# SF32LB58x register map
File version: 1.0
CPU: CM33 r0p1, little endian, MPU, FPU, 3 interrupt priority bits
Registers are 32-bit, read-write, reset 0x0 unless marked. A register's access mark holds for its fields unless they carry their own. Offsets are from the block's base; [hi:lo] are bit positions; {n}, {i} and the like mark numbered series.

## HPSYS_RCC
Base 0x40000000
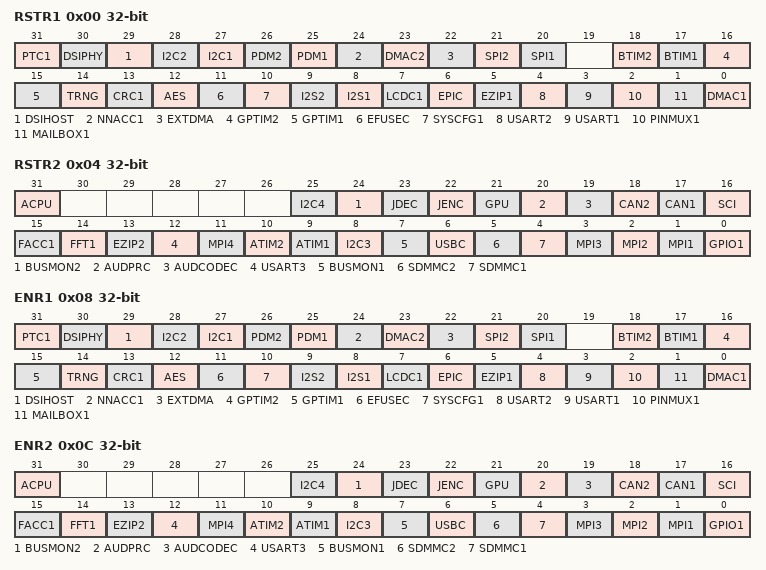
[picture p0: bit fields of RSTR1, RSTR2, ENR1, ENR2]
0x00 RSTR1 — Reset Register 1
  [31] PTC1 — 0 - no reset; 1 - reset
  [30] DSIPHY — 0 - no reset; 1 - reset
  [29] DSIHOST — 0 - no reset; 1 - reset
  [28] I2C2 — 0 - no reset; 1 - reset
  [27] I2C1 — 0 - no reset; 1 - reset
  [26] PDM2 — 0 - no reset; 1 - reset
  [25] PDM1 — 0 - no reset; 1 - reset
  [24] NNACC1 — 0 - no reset; 1 - reset
  [23] DMAC2 — 0 - no reset; 1 - reset
  [22] EXTDMA — 0 - no reset; 1 - reset
  [21] SPI2 — 0 - no reset; 1 - reset
  [20] SPI1 — 0 - no reset; 1 - reset
  [18] BTIM2 — 0 - no reset; 1 - reset
  [17] BTIM1 — 0 - no reset; 1 - reset
  [16] GPTIM2 — 0 - no reset; 1 - reset
  [15] GPTIM1 — 0 - no reset; 1 - reset
  [14] TRNG — 0 - no reset; 1 - reset
  [13] CRC1 — 0 - no reset; 1 - reset
  [12] AES — 0 - no reset; 1 - reset
  [11] EFUSEC — 0 - no reset; 1 - reset
  [10] SYSCFG1 — 0 - no reset; 1 - reset
  [9] I2S2 — 0 - no reset; 1 - reset
  [8] I2S1 — 0 - no reset; 1 - reset
  [7] LCDC1 — 0 - no reset; 1 - reset
  [6] EPIC — 0 - no reset; 1 - reset
  [5] EZIP1 — 0 - no reset; 1 - reset
  [4] USART2 — 0 - no reset; 1 - reset
  [3] USART1 — 0 - no reset; 1 - reset
  [2] PINMUX1 — 0 - no reset; 1 - reset
  [1] MAILBOX1 — 0 - no reset; 1 - reset
  [0] DMAC1 — 0 - no reset; 1 - reset
0x04 RSTR2 — Reset Register 2
  [31] ACPU — 0 - no reset; 1 - reset
  [25] I2C4 — 0 - no reset; 1 - reset
  [24] BUSMON2 — 0 - no reset; 1 - reset
  [23] JDEC — 0 - no reset; 1 - reset
  [22] JENC — 0 - no reset; 1 - reset
  [21] GPU — 0 - no reset; 1 - reset
  [20] AUDPRC — 0 - no reset; 1 - reset
  [19] AUDCODEC — 0 - no reset; 1 - reset
  [18] CAN2 — 0 - no reset; 1 - reset
  [17] CAN1 — 0 - no reset; 1 - reset
  [16] SCI — 0 - no reset; 1 - reset
  [15] FACC1 — 0 - no reset; 1 - reset
  [14] FFT1 — 0 - no reset; 1 - reset
  [13] EZIP2 — 0 - no reset; 1 - reset
  [12] USART3 — 0 - no reset; 1 - reset
  [11] MPI4 — 0 - no reset; 1 - reset
  [10] ATIM2 — 0 - no reset; 1 - reset
  [9] ATIM1 — 0 - no reset; 1 - reset
  [8] I2C3 — 0 - no reset; 1 - reset
  [7] BUSMON1 — 0 - no reset; 1 - reset
  [6] USBC — 0 - no reset; 1 - reset
  [5] SDMMC2 — 0 - no reset; 1 - reset
  [4] SDMMC1 — 0 - no reset; 1 - reset
  [3] MPI3 — 0 - no reset; 1 - reset
  [2] MPI2 — 0 - no reset; 1 - reset
  [1] MPI1 — 0 - no reset; 1 - reset
  [0] GPIO1 — 0 - no reset; 1 - reset
0x08 ENR1 — Enable Register 1
  [31] PTC1 — 0 - disabled; 1 - enabled
  [30] DSIPHY — 0 - disabled; 1 - enabled
  [29] DSIHOST — 0 - disabled; 1 - enabled
  [28] I2C2 — 0 - disabled; 1 - enabled
  [27] I2C1 — 0 - disabled; 1 - enabled
  [26] PDM2 — 0 - disabled; 1 - enabled
  [25] PDM1 — 0 - disabled; 1 - enabled
  [24] NNACC1 — 0 - disabled; 1 - enabled
  [23] DMAC2 — 0 - disabled; 1 - enabled
  [22] EXTDMA — 0 - disabled; 1 - enabled
  [21] SPI2 — 0 - disabled; 1 - enabled
  [20] SPI1 — 0 - disabled; 1 - enabled
  [18] BTIM2 — 0 - disabled; 1 - enabled
  [17] BTIM1 — 0 - disabled; 1 - enabled
  [16] GPTIM2 — 0 - disabled; 1 - enabled
  [15] GPTIM1 — 0 - disabled; 1 - enabled
  [14] TRNG — 0 - disabled; 1 - enabled
  [13] CRC1 — 0 - disabled; 1 - enabled
  [12] AES — 0 - disabled; 1 - enabled
  [11] EFUSEC — 0 - disabled; 1 - enabled
  [10] SYSCFG1 — 0 - disabled; 1 - enabled
  [9] I2S2 — 0 - disabled; 1 - enabled
  [8] I2S1 — 0 - disabled; 1 - enabled
  [7] LCDC1 — 0 - disabled; 1 - enabled
  [6] EPIC — 0 - disabled; 1 - enabled
  [5] EZIP1 — 0 - disabled; 1 - enabled
  [4] USART2 — 0 - disabled; 1 - enabled
  [3] USART1 — 0 - disabled; 1 - enabled
  [2] PINMUX1 — 0 - disabled; 1 - enabled
  [1] MAILBOX1 — 0 - disabled; 1 - enabled
  [0] DMAC1 — 0 - disabled; 1 - enabled
0x0C ENR2 — Enable Register 2
  [31] ACPU — 0 - disabled; 1 - enabled
  [25] I2C4 — 0 - disabled; 1 - enabled
  [24] BUSMON2 — 0 - disabled; 1 - enabled
  [23] JDEC — 0 - disabled; 1 - enabled
  [22] JENC — 0 - disabled; 1 - enabled
  [21] GPU — 0 - disabled; 1 - enabled
  [20] AUDPRC — 0 - disabled; 1 - enabled
  [19] AUDCODEC — 0 - disabled; 1 - enabled
  [18] CAN2 — 0 - disabled; 1 - enabled
  [17] CAN1 — 0 - disabled; 1 - enabled
  [16] SCI — 0 - disabled; 1 - enabled
  [15] FACC1 — 0 - disabled; 1 - enabled
  [14] FFT1 — 0 - disabled; 1 - enabled
  [13] EZIP2 — 0 - disabled; 1 - enabled
  [12] USART3 — 0 - disabled; 1 - enabled
  [11] MPI4 — 0 - disabled; 1 - enabled
  [10] ATIM2 — 0 - disabled; 1 - enabled
  [9] ATIM1 — 0 - disabled; 1 - enabled
  [8] I2C3 — 0 - disabled; 1 - enabled
  [7] BUSMON1 — 0 - disabled; 1 - enabled
  [6] USBC — 0 - disabled; 1 - enabled
  [5] SDMMC2 — 0 - disabled; 1 - enabled
  [4] SDMMC1 — 0 - disabled; 1 - enabled
  [3] MPI3 — 0 - disabled; 1 - enabled
  [2] MPI2 — 0 - disabled; 1 - enabled
  [1] MPI1 — 0 - disabled; 1 - enabled
  [0] GPIO1 — 0 - disabled; 1 - enabled
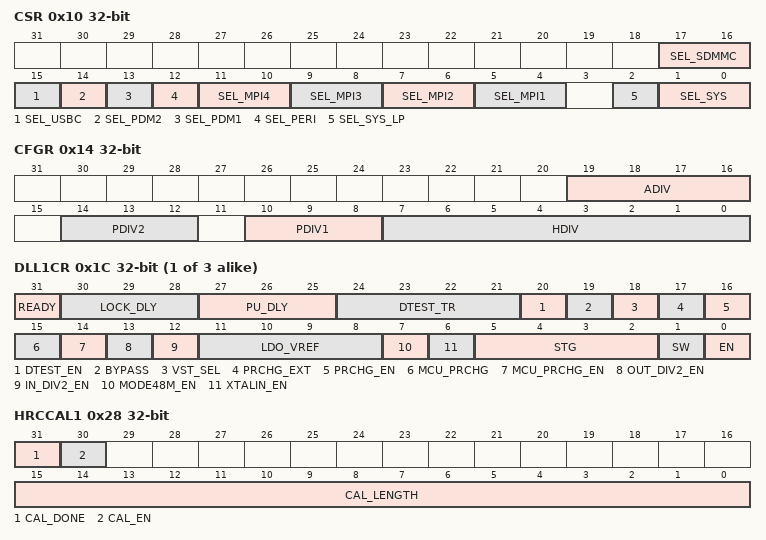
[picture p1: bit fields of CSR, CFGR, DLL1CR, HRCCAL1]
0x10 CSR — Clock Select Register
  [17:16] SEL_SDMMC — select SDMMC function clock 0 - clk_sys; 1 - reserved; 2 - dll2; 3 - dll3
  [15] SEL_USBC — select USB source clock 0 - clk_sys; 1 - dll3
  [14] SEL_PDM2 — 0 - clk_sys; 1 - dll2
  [13] SEL_PDM1 — 0 - clk_sys; 1 - dll2
  [12] SEL_PERI — select clk_peri source used by USART/SPI/CAN/I2C 0 - hrc48; 1 - hxt48
  [2n+3:2n+2] SEL_MPI{n} (n=1..4) — selet MPI{n} function clock 0 - clk_sys; 1 - reserved; 2 - dll2; 3 - dll3
  [2] SEL_SYS_LP — select clk_sys source 0 - selected by SEL_SYS; 1 - clk_lp
  [1:0] SEL_SYS — select clk_sys source 0 - hrc48; 1 - hxt48; 2 - reserved; 3 - dll1
0x14 CFGR — Clock Configuration Register
  [19:16] ADIV — hclk_auxsys = clk_sys / ADIV if ADIV=0, hclk_auxsys = clk_sys
  [14:12] PDIV2 — pclk2 = hclk / (2^PDIV2), by default divided by 128
  [10:8] PDIV1 — pclk1 = hclk / (2^PDIV1), by default divided by 2
  [7:0] HDIV — hclk = hclk_auxsys / HDIV = clk_sys / (ADIV*HDIV) if HDIV=0, hclk = hclk_auxsys
0x18 USBCR — USBC Register
  [2:0] DIV — USB function clock is USB source clock divided by DIV. After divider, USB function clock must be 60MHz.
{0x18+4i} DLL{i}CR (i=1..3) — DLL{i} Control Register
  [31] READY — 0: dll not ready 1: dll ready
  [30:28] LOCK_DLY
  [27:25] PU_DLY
  [24:21] DTEST_TR
  [20] DTEST_EN
  [19] BYPASS
  [18] VST_SEL
  [17] PRCHG_EXT
  [16] PRCHG_EN
  [15] MCU_PRCHG
  [14] MCU_PRCHG_EN
  [13] OUT_DIV2_EN — 0: dll output not divided 1: dll output divided by 2
  [12] IN_DIV2_EN
  [11:8] LDO_VREF
  [7] MODE48M_EN
  [6] XTALIN_EN
  [5:2] STG — DLL lock freqency is decided by STG. DLL output frequency is: 0: 192MHz(if OUT_DIV2_EN=1) or 384MHz(if OUT_DIV2_EN=0) 1: 168MHz(if OUT_DIV2_EN=1) or 336MHz(if OUT_DIV2_EN=0) 2: 144MHz(if OUT_DIV2_EN=1) or 288MHz(if OUT_DIV2_EN=0) 3: 120MHz(if OUT_DIV2_EN=1) or 240MHz(if OUT_DIV2_EN=0) 4: 96MHz(if OUT_DIV2_EN=1) or 192MHz(if OUT_DIV2_EN=0)
  [1] SW
  [0] EN — 0: dll disabled 1: dll enabled
0x28 HRCCAL1 — HRC Calibration Register 1
  [31] CAL_DONE — Calibration done. After a new calibration started, results should be processed only when cal_done asserted.
  [30] CAL_EN — Calibration enble. Set to 0 to clear result, then set to 1 to start a new calibration
  [15:0] CAL_LENGTH — Target hxt48 cycles during calibration
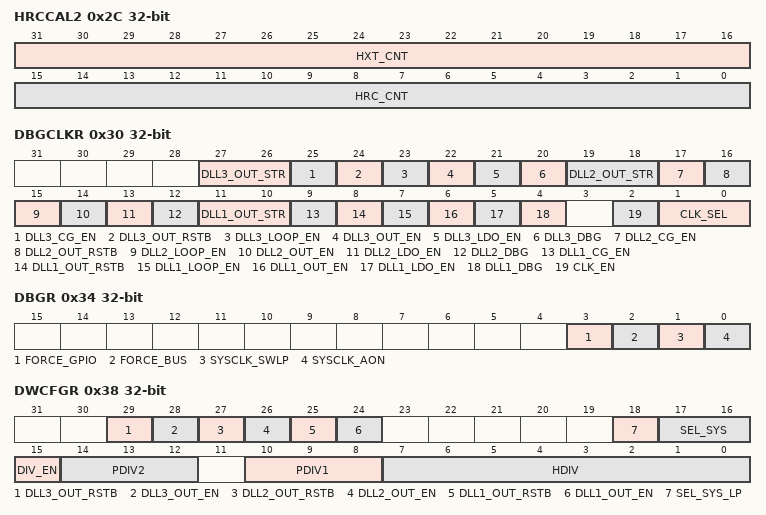
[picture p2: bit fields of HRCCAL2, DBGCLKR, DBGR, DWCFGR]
0x2C HRCCAL2 — HRC Calibration Register 2
  [31:16] HXT_CNT — Total hxt48 cycles during calibration
  [15:0] HRC_CNT — Total hrc48 cycles during calibration
0x30 DBGCLKR — Debug Clock Register
  [27:26] DLL3_OUT_STR — for debug only
  [25] DLL3_CG_EN — for debug only
  [24] DLL3_OUT_RSTB — for debug only
  [23] DLL3_LOOP_EN — for debug only
  [22] DLL3_OUT_EN — for debug only
  [21] DLL3_LDO_EN — for debug only
  [20] DLL3_DBG — for debug only
  [19:18] DLL2_OUT_STR — for debug only
  [17] DLL2_CG_EN — for debug only
  [16] DLL2_OUT_RSTB — for debug only
  [15] DLL2_LOOP_EN — for debug only
  [14] DLL2_OUT_EN — for debug only
  [13] DLL2_LDO_EN — for debug only
  [12] DLL2_DBG — for debug only
  [11:10] DLL1_OUT_STR — for debug only
  [9] DLL1_CG_EN — for debug only
  [8] DLL1_OUT_RSTB — for debug only
  [7] DLL1_LOOP_EN — for debug only
  [6] DLL1_OUT_EN — for debug only
  [5] DLL1_LDO_EN — for debug only
  [4] DLL1_DBG — for debug only
  [2] CLK_EN — for debug only
  [1:0] CLK_SEL — for debug only
0x34 DBGR — Debug Register
  [3] FORCE_GPIO — for debug only
  [2] FORCE_BUS — for debug only
  [1] SYSCLK_SWLP — for debug only
  [0] SYSCLK_AON — for debug only
0x38 DWCFGR — Deep WFI mode Clock Configuration Register
  [29] DLL3_OUT_RSTB — for debug only
  [28] DLL3_OUT_EN — for debug only
  [27] DLL2_OUT_RSTB — for debug only
  [26] DLL2_OUT_EN — for debug only
  [25] DLL1_OUT_RSTB — for debug only
  [24] DLL1_OUT_EN — for debug only
  [18] SEL_SYS_LP — select clk_sys source during deep WFI 0 - selected by SEL_SYS; 1 - clk_lp
  [17:16] SEL_SYS — select clk_sys source during deep WFI 0 - hrc48; 1 - hxt48; 2 - reserved; 3 - dll1
  [15] DIV_EN — enable PDIV1, PDIV2 and HDIV reconfiguration during deep wfi
  [14:12] PDIV2 — pclk2 = hclk / (2^PDIV2) during deep WFI
  [10:8] PDIV1 — pclk = hclk / (2^PDIV1) during deep WFI
  [7:0] HDIV — hclk = hclk_auxsys / HDIV during deep WFI
